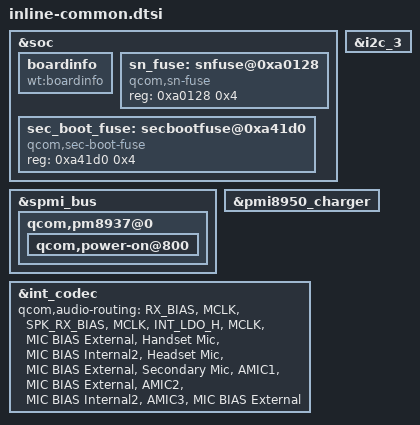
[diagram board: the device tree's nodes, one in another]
&soc {
	boardinfo {
		compatible = "wt:boardinfo";
	};
};

&i2c_3 {
	status = "ok";
};

&spmi_bus {
	qcom,pm8937@0 {
		qcom,power-on@800 {
			/delete-property/ qcom,store-hard-reset-reason;
		};
	};
};

&pmi8950_charger {
	/delete-property/ qcom,autoadjust-vfloat;
};

&soc {
	sn_fuse: snfuse@0xa0128 {
		compatible = "qcom,sn-fuse";
		reg = <0xa0128 0x4>;
		reg-names = "sn-base";
	};

	sec_boot_fuse: secbootfuse@0xa41d0 {
		compatible = "qcom,sec-boot-fuse";
		reg = <0xa41d0 0x4>;
		reg-names = "sec-boot-base";
	};
};

&int_codec {
	/* Removed: \0WSA_SPK OUT\0VDD_WSA_SWITCH\0SpkrMono WSA_IN\0WSA_SPK OUT */
	qcom,audio-routing =
		"RX_BIAS", "MCLK",
		"SPK_RX_BIAS", "MCLK",
		"INT_LDO_H", "MCLK",
		"MIC BIAS External", "Handset Mic",
		"MIC BIAS Internal2", "Headset Mic",
		"MIC BIAS External", "Secondary Mic",
		"AMIC1", "MIC BIAS External",
		"AMIC2", "MIC BIAS Internal2",
		"AMIC3", "MIC BIAS External";
};
